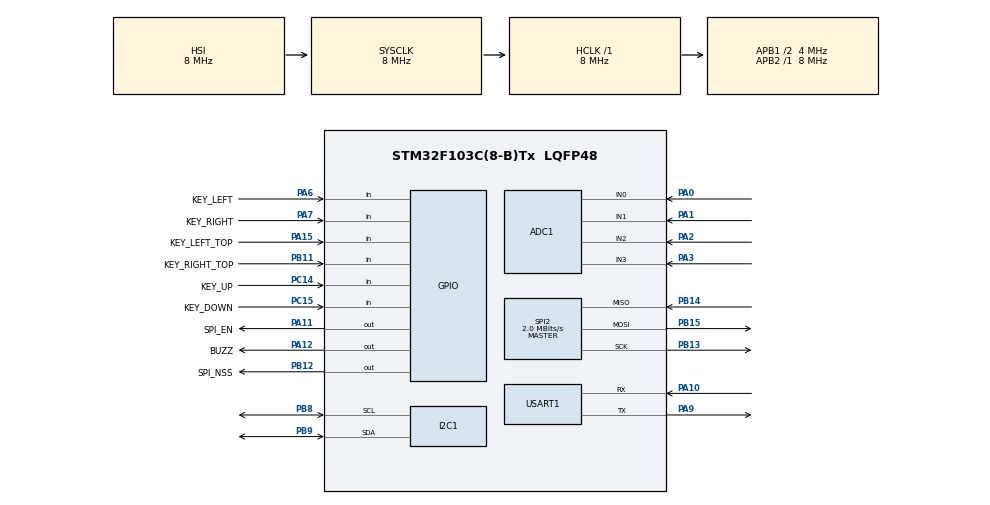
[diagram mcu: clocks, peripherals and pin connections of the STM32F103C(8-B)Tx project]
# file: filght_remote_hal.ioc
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ADC1.Channel-0\#ChannelRegularConversion=ADC_CHANNEL_0
ADC1.Channel-1\#ChannelRegularConversion=ADC_CHANNEL_1
ADC1.Channel-2\#ChannelRegularConversion=ADC_CHANNEL_3
ADC1.Channel-3\#ChannelRegularConversion=ADC_CHANNEL_2
ADC1.ContinuousConvMode=ENABLE
ADC1.NbrOfConversion=4
ADC1.NbrOfConversionFlag=1
ADC1.Rank-0\#ChannelRegularConversion=1
ADC1.Rank-1\#ChannelRegularConversion=2
ADC1.Rank-2\#ChannelRegularConversion=3
ADC1.Rank-3\#ChannelRegularConversion=4
ADC1.SamplingTime-0\#ChannelRegularConversion=ADC_SAMPLETIME_13CYCLES_5
ADC1.SamplingTime-1\#ChannelRegularConversion=ADC_SAMPLETIME_13CYCLES_5
ADC1.SamplingTime-2\#ChannelRegularConversion=ADC_SAMPLETIME_13CYCLES_5
ADC1.SamplingTime-3\#ChannelRegularConversion=ADC_SAMPLETIME_13CYCLES_5
ADC1.master=1
Dma.ADC1.0.Direction=DMA_PERIPH_TO_MEMORY
Dma.ADC1.0.Instance=DMA1_Channel1
Dma.ADC1.0.MemDataAlignment=DMA_MDATAALIGN_HALFWORD
Dma.ADC1.0.MemInc=DMA_MINC_ENABLE
Dma.ADC1.0.Mode=DMA_CIRCULAR
Dma.ADC1.0.PeriphDataAlignment=DMA_PDATAALIGN_HALFWORD
Dma.ADC1.0.PeriphInc=DMA_PINC_DISABLE
Dma.ADC1.0.Priority=DMA_PRIORITY_LOW
Dma.Request0=ADC1
I2C1.I2C_Mode=I2C_Fast
Mcu.Family=STM32F1
Mcu.Name=STM32F103C(8-B)Tx
Mcu.Package=LQFP48
NVIC.DMA1_Channel1_IRQn=false\:0\:0\:false\:false\:true\:false\:false\:false
NVIC.PriorityGroup=NVIC_PRIORITYGROUP_4
PA0-WKUP.Signal=ADCx_IN0
PA1.Signal=ADCx_IN1
PA10.Mode=Asynchronous
PA10.Signal=USART1_RX
PA11.GPIO_Label=SPI_EN
PA11.Signal=GPIO_Output
PA12.GPIO_Label=BUZZ
PA12.PinState=GPIO_PIN_RESET
PA12.Signal=GPIO_Output
PA13.Mode=Serial_Wire
PA13.Signal=SYS_JTMS-SWDIO
PA14.Mode=Serial_Wire
PA14.Signal=SYS_JTCK-SWCLK
PA15.GPIO_Label=KEY_LEFT_TOP
PA15.GPIO_PuPd=GPIO_PULLUP
PA15.Signal=GPIO_Input
PA2.Signal=ADCx_IN2
PA3.Signal=ADCx_IN3
PA6.GPIO_Label=KEY_LEFT
PA6.GPIO_PuPd=GPIO_PULLUP
PA6.Signal=GPIO_Input
PA7.GPIO_Label=KEY_RIGHT
PA7.GPIO_PuPd=GPIO_PULLUP
PA7.Signal=GPIO_Input
PA9.Mode=Asynchronous
PA9.Signal=USART1_TX
PB8.Mode=I2C
PB8.Signal=I2C1_SCL
PB9.Mode=I2C
PB9.Signal=I2C1_SDA
PB11.GPIO_Label=KEY_RIGHT_TOP
PB11.GPIO_PuPd=GPIO_PULLUP
PB11.Signal=GPIO_Input
PB12.GPIO_Label=SPI_NSS
PB12.PinState=GPIO_PIN_SET
PB12.Signal=GPIO_Output
PB13.Mode=Full_Duplex_Master
PB13.Signal=SPI2_SCK
PB14.Mode=Full_Duplex_Master
PB14.Signal=SPI2_MISO
PB15.Mode=Full_Duplex_Master
PB15.Signal=SPI2_MOSI
PC14-OSC32_IN.GPIO_Label=KEY_UP
PC14-OSC32_IN.GPIO_PuPd=GPIO_PULLUP
PC14-OSC32_IN.Signal=GPIO_Input
PC15-OSC32_OUT.GPIO_Label=KEY_DOWN
PC15-OSC32_OUT.GPIO_PuPd=GPIO_PULLUP
PC15-OSC32_OUT.Signal=GPIO_Input
PD0-OSC_IN.Mode=HSE-External-Oscillator
PD0-OSC_IN.Signal=RCC_OSC_IN
PD1-OSC_OUT.Mode=HSE-External-Oscillator
PD1-OSC_OUT.Signal=RCC_OSC_OUT
ProjectManager.HeapSize=0x200
ProjectManager.StackSize=0x400
ProjectManager.TargetToolchain=MDK-ARM V5.32
RCC.AHBFreq_Value=8000000
RCC.APB1CLKDivider=RCC_HCLK_DIV2
RCC.APB1Freq_Value=4000000
RCC.APB1TimFreq_Value=8000000
RCC.APB2Freq_Value=8000000
RCC.APB2TimFreq_Value=8000000
RCC.HCLKFreq_Value=8000000
RCC.PLLMUL=RCC_PLL_MUL9
RCC.SYSCLKFreq_VALUE=8000000
RCC.USBFreq_Value=36000000
SH.ADCx_IN0.0=ADC1_IN0,IN0
SH.ADCx_IN1.0=ADC1_IN1,IN1
SH.ADCx_IN2.0=ADC1_IN2,IN2
SH.ADCx_IN3.0=ADC1_IN3,IN3
SPI2.BaudRatePrescaler=SPI_BAUDRATEPRESCALER_2
SPI2.CalculateBaudRate=2.0 MBits/s
SPI2.Direction=SPI_DIRECTION_2LINES
SPI2.Mode=SPI_MODE_MASTER
SPI2.VirtualType=VM_MASTER
USART1.VirtualMode=VM_ASYNC
board=custom

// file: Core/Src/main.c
/* USER CODE BEGIN Header */
/**
  ******************************************************************************
  * @file           : main.c
  * @brief          : Main program body
  ******************************************************************************
  * @attention
  *
  * Copyright (c) 2026 STMicroelectronics.
  * All rights reserved.
  *
  * This software is licensed under terms that can be found in the LICENSE file
  * in the root directory of this software component.
  * If no LICENSE file comes with this software, it is provided AS-IS.
  *
  ******************************************************************************
  */
/* USER CODE END Header */
#include "main.h"
#include "adc.h"
#include "dma.h"
#include "i2c.h"
#include "spi.h"
#include "usart.h"
#include "gpio.h"

/* USER CODE BEGIN Includes */
#include "common_debug.h"
#include "application_freertos_task.h"
#include "nRF24L01P.h"
/* USER CODE END Includes */

void SystemClock_Config(void);

int main(void)
{

  /* MCU Configuration--------------------------------------------------------*/

  /* Reset of all peripherals, Initializes the Flash interface and the Systick. */
  HAL_Init();

  /* Configure the system clock */
  SystemClock_Config();

  /* Initialize all configured peripherals */
  MX_GPIO_Init();
  MX_DMA_Init();
  MX_USART1_UART_Init();
  MX_SPI2_Init();
  MX_I2C1_Init();
  MX_ADC1_Init();
  /* USER CODE BEGIN 2 */
//HAL_UART_Transmit(&huart3, (uint8_t *)"Hello World\r\n", 13, 1000);
//使用c语言的printf
//debug_printf("Hello Remote\r\n");
//还没有启动FREERTOS只能用HAL_Delay来延时
Int_nRF24L01P_Init();
application_freertos_start();

//启动FREERTOS,然后续的任务切换到FREERTOS的任务中去执行

  /* USER CODE END 2 */

  /* Infinite loop */
  while (1)
  {

  }
}

void SystemClock_Config(void)
{
  RCC_OscInitTypeDef RCC_OscInitStruct = {0};
  RCC_ClkInitTypeDef RCC_ClkInitStruct = {0};
  RCC_PeriphCLKInitTypeDef PeriphClkInit = {0};

  /** Initializes the RCC Oscillators according to the specified parameters
  * in the RCC_OscInitTypeDef structure.
  */
  RCC_OscInitStruct.OscillatorType = RCC_OSCILLATORTYPE_HSI;
  RCC_OscInitStruct.HSIState = RCC_HSI_ON;
  RCC_OscInitStruct.HSICalibrationValue = RCC_HSICALIBRATION_DEFAULT;
  RCC_OscInitStruct.PLL.PLLState = RCC_PLL_NONE;
  if (HAL_RCC_OscConfig(&RCC_OscInitStruct) != HAL_OK)
  {
    Error_Handler();
  }

  /** Initializes the CPU, AHB and APB buses clocks
  */
  RCC_ClkInitStruct.ClockType = RCC_CLOCKTYPE_HCLK|RCC_CLOCKTYPE_SYSCLK
                              |RCC_CLOCKTYPE_PCLK1|RCC_CLOCKTYPE_PCLK2;
  RCC_ClkInitStruct.SYSCLKSource = RCC_SYSCLKSOURCE_HSI;
  RCC_ClkInitStruct.AHBCLKDivider = RCC_SYSCLK_DIV1;
  RCC_ClkInitStruct.APB1CLKDivider = RCC_HCLK_DIV2;
  RCC_ClkInitStruct.APB2CLKDivider = RCC_HCLK_DIV1;

  if (HAL_RCC_ClockConfig(&RCC_ClkInitStruct, FLASH_LATENCY_0) != HAL_OK)
  {
    Error_Handler();
  }
  PeriphClkInit.PeriphClockSelection = RCC_PERIPHCLK_ADC;
  PeriphClkInit.AdcClockSelection = RCC_ADCPCLK2_DIV2;
  if (HAL_RCCEx_PeriphCLKConfig(&PeriphClkInit) != HAL_OK)
  {
    Error_Handler();
  }
}

void Error_Handler(void)
{
  __disable_irq();
  while (1)
  {
  }
}
